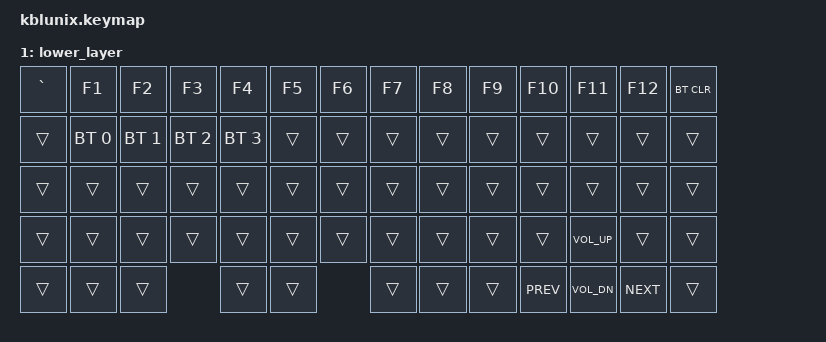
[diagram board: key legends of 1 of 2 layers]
#include <behaviors.dtsi>
#include <dt-bindings/zmk/keys.h>
#include <dt-bindings/zmk/bt.h>
#include <dt-bindings/zmk/display.h>

/ {
        keymap {
                compatible = "zmk,keymap";

                default_layer {
//-------this is commented in AZERTY but written down in QWERTY----------------------------------------------
// |    esc   |     1    |     2    |     3    |     4    |     5    |----------|     6    |     7    |     8    |     9    |     0    |     )    |     =    |    bks   |
// |    tab   |     A    |     Z    |     E    |     R    |     T    |----------|     Y    |     U    |     I    |     O    |     P    |     ^    |     $    |     *    |
// |    < >   |     Q    |     S    |     D    |     F    |     G    |----------|     H    |     J    |     K    |     L    |     M    |     ù    |    ntr   |
// |    sft   |     W    |     X    |     C    |     V    |     B    |----------|     N    |     ,    |     ;    |     :    |     !    |    upw   |
// |    crl   |    win   |    alt   |          |    spc   |    hom   |----------|          |    end   |    spc   |    alt   |    lft   |    dwn   |    rgt   |    fn    |
                        bindings = <
   &kp ESC    &kp N1    &kp N2    &kp N3     &kp N4     &kp N5               &kp N6     &kp N7  &kp N8     &kp N9    &kp N0    &kp MINUS  &kp EQUAL  &kp BSPC
   &kp TAB    &kp Q     &kp W     &kp E      &kp R      &kp T                &kp Y      &kp U   &kp I      &kp O     &kp P     &kp LBKT   &kp RBKT   &kp BSLH
   &kp NUBS   &kp A     &kp S     &kp D      &kp F      &kp G                &kp H      &kp J   &kp K      &kp L     &kp SEMI  &kp SQT    &kp ENTER
   &kp LSHFT  &kp Z     &kp X     &kp C      &kp V      &kp B                &kp N      &kp M   &kp COMMA  &kp DOT   &kp SLASH &kp UP
   &kp LCTRL  &kp LGUI  &kp LALT             &kp SPACE  &kp HOME                        &kp END &kp SPACE  &kp RALT  &kp LEFT  &kp DOWN   &kp RIGHT  &mo 1
                        >;
                };
                lower_layer {
//-------this is commented in AZERTY but written down in QWERTY----------------------------------------------
// |     `    |    F1    |    F2    |    F3    |    F4    |    F5    |----------|    F6    |    F7    |    F8    |    F9    |   F10    |   F11    |   F12    |          |
// |          |   BT1    |   BT2    |   BT3    |   BT4    |   BT5    |----------|          |          |          |          |          |          |          |          |
// |          |          |          |          |          |          |----------|          |          |          |          |          |          |          |
// |          |          |          |          |          |          |----------|          |          |          |          |          |   VL_UP  |
// |          |          |          |          |          |          |----------|          |          |          |          |   prev   |   VL_DN  |   next   |          |
                        bindings = <
   &kp GRAVE    &kp F1       &kp F2       &kp F3       &kp F4       &kp F5                &kp F6       &kp F7       &kp F8       &kp F9       &kp F10      &kp F11      &kp F12      &bt BT_CLR
   &trans       &bt BT_SEL 0 &bt BT_SEL 1 &bt BT_SEL 2 &bt BT_SEL 3 &trans                &trans       &trans       &trans       &trans       &trans       &trans       &trans       &trans
   &trans       &trans       &trans       &trans       &trans       &trans                &trans       &trans       &trans       &trans       &trans       &trans       &trans       &trans
   &trans       &trans       &trans       &trans       &trans       &trans                &trans       &trans       &trans       &trans       &trans       &kp C_VOL_UP &trans       &trans       
   &trans       &trans       &trans                    &trans       &trans                             &trans       &trans       &trans       &kp C_PREV   &kp C_VOL_DN &kp C_NEXT   &trans       
                        >;
                };
        };
};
